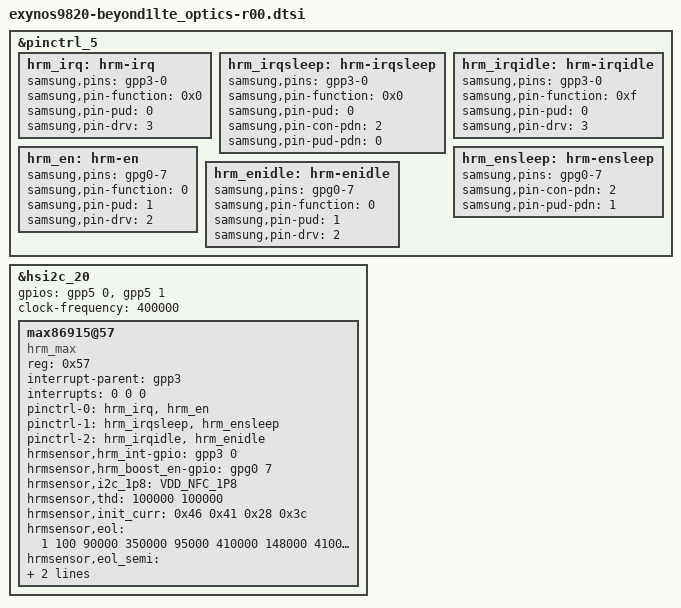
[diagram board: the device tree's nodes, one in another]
/*
 * SAMSUNG UNIVERSAL9820 board device tree source
 *
 * Copyright (c) 2018 Samsung Electronics Co., Ltd.
 *		http://www.samsung.com
 *
 * This program is free software; you can redistribute it and/or modify
 * it under the terms of the GNU General Public License version 2 as
 * published by the Free Software Foundation.
 */

&pinctrl_5 {
	hrm_irq: hrm-irq {
		samsung,pins = "gpp3-0";
		samsung,pin-function = <0x0>;
		samsung,pin-pud = <0>;
		samsung,pin-drv = <3>;
	};

	hrm_irqsleep: hrm-irqsleep {
		samsung,pins = "gpp3-0";
		samsung,pin-function = <0x0>;
		samsung,pin-pud = <0>;
		samsung,pin-con-pdn = <2>;
		samsung,pin-pud-pdn = <0>;
	};

	hrm_irqidle: hrm-irqidle {
		samsung,pins = "gpp3-0";
		samsung,pin-function = <0xf>;
		samsung,pin-pud = <0>;
		samsung,pin-drv = <3>;
	};

	hrm_en: hrm-en {
		samsung,pins = "gpg0-7";
		samsung,pin-function = <0>;
		samsung,pin-pud = <1>;
		samsung,pin-drv = <2>;
	};

	hrm_ensleep: hrm-ensleep {
		samsung,pins = "gpg0-7";
		samsung,pin-con-pdn = <2>;
		samsung,pin-pud-pdn = <1>;
	};

	hrm_enidle: hrm-enidle {
		samsung,pins = "gpg0-7";
		samsung,pin-function = <0>;
		samsung,pin-pud = <1>;
		samsung,pin-drv = <2>;
	};
};

&hsi2c_20 {
	gpios = <&gpp5 0 0 &gpp5 1 0>;
	status = "okay";
	clock-frequency = <400000>;

	max86915@57 {
		compatible = "hrm_max";
		reg = <0x57>;
		interrupt-parent = <&gpp3>;
		interrupts = <0 0 0>;
		pinctrl-names = "default", "sleep", "idle";
		pinctrl-0 = <&hrm_irq &hrm_en>;
		pinctrl-1 = <&hrm_irqsleep &hrm_ensleep>;
		pinctrl-2 = <&hrm_irqidle &hrm_enidle>;
		hrmsensor,hrm_int-gpio = <&gpp3 0 0>;
		hrmsensor,hrm_boost_en-gpio = <&gpg0 7 0>;
		hrmsensor,i2c_1p8 = "VDD_NFC_1P8";
		hrmsensor,thd = <100000 100000>;
		hrmsensor,init_curr = <0x46 0x41 0x28 0x3c>;
		hrmsensor,eol = <1 100		/* SYSTEM NOISE */
				90000 350000	/* MID */
				95000 410000
				148000 410000
				132000 410000
				133000 410000	/* HIGH */
				143000 410000
				185000 515000
				167000 515000
				0 150000		/* XTALK */
				0 150000
				0 270000
				0 270000
				1 300			/* NOISE */
				1 300
				1 300
				1 300
				384 416>;		/* FREQUENCY */
		hrmsensor,eol_semi = <1 100 	/* SYSTEM NOISE */
				3500 350000 /* MID */
				3500 350000
				4500 524287
				4500 470000
				4000 400000 /* HIGH */
				4000 430000
				5000 524287
				5000 524287
				0 150000		/* XTALK */
				0 150000
				0 270000
				0 270000
				1 300			/* NOISE */
				1 300
				1 300
				1 300
				384 416>;		/* FREQUENCY */
		hrmsensor,eol_xtalk = <0 40000>;
	};
};
